AUTOSAR XML (schema 4-3-0)
# SPDX-License-Identifier: MIT
# canbus-interop fixture: AUTOSAR 4 CAN cluster: Intel and Motorola signals, standard and extended identifiers, LINEAR, TEXTTABLE, SCALE_LINEAR_AND_TEXTTABLE and IDENTICAL compu methods, signed base types (2C), init values
standard types defined: sint8, sint16, sint32
package /Cluster
  can cluster Body: baudrate=500000
    can physical channel Channel
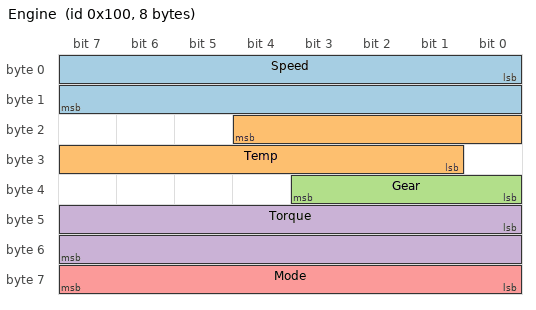
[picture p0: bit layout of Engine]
      frame Engine: id 0x100, frame-length=8, can-addressing-mode=STANDARD
        pdu EnginePdu: length=8
          signal Speed: start 0, 16 bit, little-endian, compu {phys=raw*0.125-40}, unit=rpm, transfer-property=PENDING
          signal Temp: start 20, 12 bit, big-endian, init-value=40, compu {identical}, transfer-property=PENDING
          signal Gear: start 32, 4 bit, little-endian, compu {0=Neutral, 1=First, 2=Second, 15=Invalid}, transfer-property=PENDING
          signal Torque: start 40, 16 bit, little-endian, base-type=sint16, compu {phys=raw*0.5}, transfer-property=PENDING
          signal Mode: start 56, 8 bit, little-endian, compu {254=Error, 255=NotAvailable, phys=raw*0.5 for raw 0..253}, transfer-property=PENDING
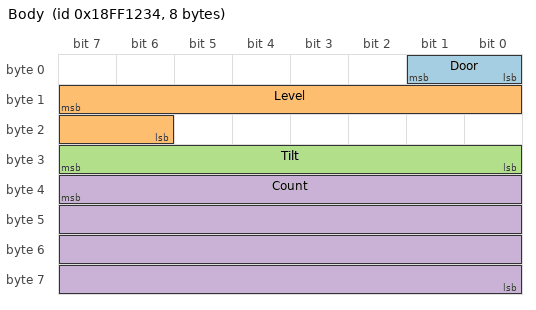
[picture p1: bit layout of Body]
      frame Body: id 0x18FF1234, frame-length=8, can-addressing-mode=EXTENDED
        pdu BodyPdu: length=8
          signal Door: start 0, 2 bit, little-endian, compu {0=Closed, 1=Open, 2=Ajar}, transfer-property=PENDING
          signal Level: start 15, 10 bit, big-endian, init-value=512, compu {phys=raw*0.25-100}, transfer-property=PENDING
          signal Tilt: start 24, 8 bit, little-endian, base-type=sint8, compu {phys=raw}, transfer-property=PENDING
          signal Count: start 39, 32 bit, big-endian, transfer-property=PENDING
package /Units
  unit rpm: display-name=rpm
